# N32G05x register map
Vendor: Nationstech Ltd.; File version: 1.0
Registers are 32-bit, read-write, reset 0x0 unless marked. A register's access mark holds for its fields unless they carry their own. Offsets are from the block's base; [hi:lo] are bit positions; {n}, {i} and the like mark numbered series; 'fields as' and 'values as' point back to an identical list.

## RCC — Reset and clock control
Base 0x40021000
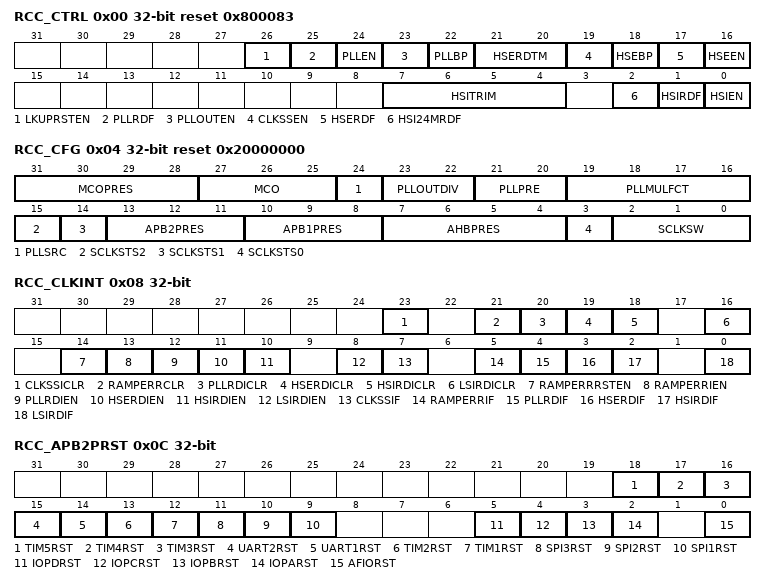
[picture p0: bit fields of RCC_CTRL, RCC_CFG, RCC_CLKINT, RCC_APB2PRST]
0x00 RCC_CTRL reset 0x800083 (reset mask 0x3CB00FB)
  [26] LKUPRSTEN, [25] PLLRDF, [24] PLLEN, [23] PLLOUTEN, [22] PLLBP, [21:20] HSERDTM, [19] CLKSSEN, [18] HSEBP, [17] HSERDF, [16] HSEEN, [7:4] HSITRIM, [2] HSI24MRDF, [1] HSIRDF, [0] HSIEN
0x04 RCC_CFG reset 0x20000000
  [31:28] MCOPRES, [27:25] MCO, [24] PLLSRC, [23:22] PLLOUTDIV, [21:20] PLLPRE, [19:16] PLLMULFCT, [15] SCLKSTS2, [14] SCLKSTS1, [13:11] APB2PRES, [10:8] APB1PRES, [7:4] AHBPRES, [3] SCLKSTS0, [2:0] SCLKSW
0x08 RCC_CLKINT
  [23] CLKSSICLR, [21] RAMPERRCLR, [20] PLLRDICLR, [19] HSERDICLR, [18] HSIRDICLR, [16] LSIRDICLR, [14] RAMPERRRSTEN, [13] RAMPERRIEN, [12] PLLRDIEN, [11] HSERDIEN, [10] HSIRDIEN, [8] LSIRDIEN, [7] CLKSSIF, [5] RAMPERRIF, [4] PLLRDIF, [3] HSERDIF, [2] HSIRDIF, [0] LSIRDIF
0x0C RCC_APB2PRST (reset mask 0x2769D)
  [18] TIM5RST, [17] TIM4RST, [16] TIM3RST, [15] UART2RST, [14] UART1RST, [13] TIM2RST, [12] TIM1RST, [11] SPI3RST, [10] SPI2RST, [9] SPI1RST, [5] IOPDRST, [4] IOPCRST, [3] IOPBRST, [2] IOPARST, [0] AFIORST
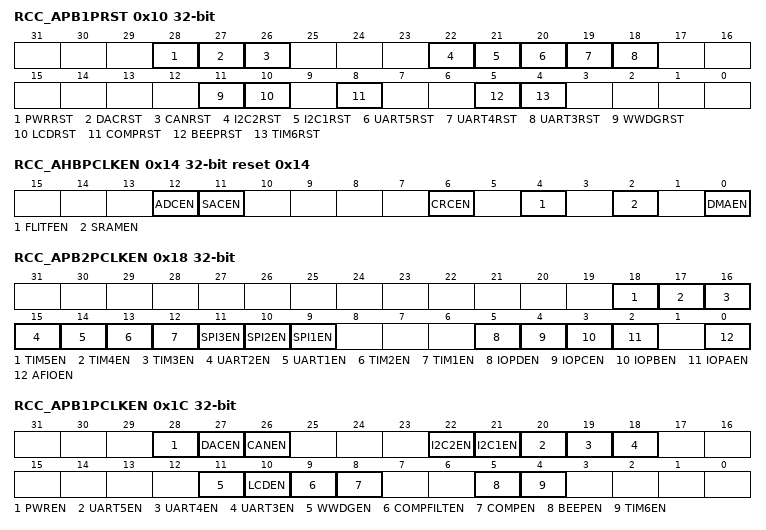
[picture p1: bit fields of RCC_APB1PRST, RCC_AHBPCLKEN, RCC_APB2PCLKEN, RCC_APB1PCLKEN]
0x10 RCC_APB1PRST (reset mask 0x1066083A)
  [28] PWRRST, [27] DACRST, [26] CANRST, [22] I2C2RST, [21] I2C1RST, [20] UART5RST, [19] UART4RST, [18] UART3RST, [11] WWDGRST, [10] LCDRST, [8] COMPRST, [5] BEEPRST, [4] TIM6RST
0x14 RCC_AHBPCLKEN reset 0x14 (reset mask 0x10F7)
  [12] ADCEN, [11] SACEN, [6] CRCEN, [4] FLITFEN, [2] SRAMEN, [0] DMAEN
0x18 RCC_APB2PCLKEN (reset mask 0x769D)
  [18] TIM5EN, [17] TIM4EN, [16] TIM3EN, [15] UART2EN, [14] UART1EN, [13] TIM2EN, [12] TIM1EN, [11] SPI3EN, [10] SPI2EN, [9] SPI1EN, [5] IOPDEN, [4] IOPCEN, [3] IOPBEN, [2] IOPAEN, [0] AFIOEN
0x1C RCC_APB1PCLKEN (reset mask 0x90660B3E)
  [28] PWREN, [27] DACEN, [26] CANEN, [22] I2C2EN, [21] I2C1EN, [20] UART5EN, [19] UART4EN, [18] UART3EN, [11] WWDGEN, [10] LCDEN, [9] COMPFILTEN, [8] COMPEN, [5] BEEPEN, [4] TIM6EN
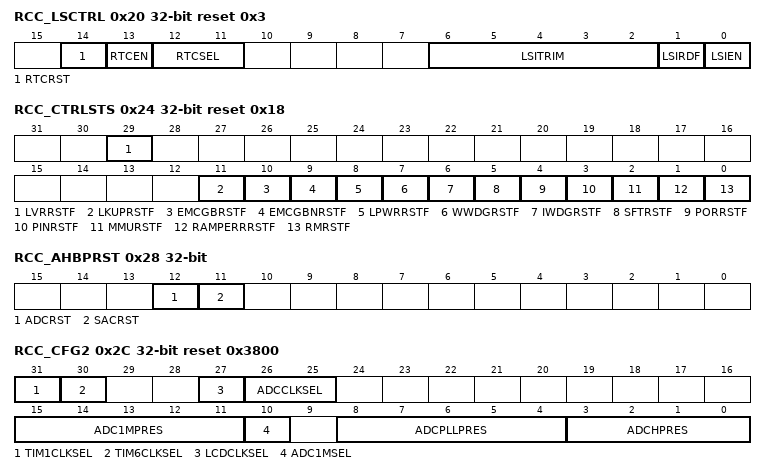
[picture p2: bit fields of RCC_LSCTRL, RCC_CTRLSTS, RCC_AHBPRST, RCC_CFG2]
0x20 RCC_LSCTRL reset 0x3 (reset mask 0x3FF)
  [14] RTCRST
  [13] RTCEN
  [12:11] RTCSEL
  [6:2] LSITRIM
  [1] LSIRDF — LSIRD
  [0] LSIEN
0x24 RCC_CTRLSTS reset 0x18 (reset mask 0xFFF)
  [29] LVRRSTF, [11] LKUPRSTF, [10] EMCGBRSTF, [9] EMCGBNRSTF, [8] LPWRRSTF, [7] WWDGRSTF, [6] IWDGRSTF, [5] SFTRSTF, [4] PORRSTF, [3] PINRSTF, [2] MMURSTF, [1] RAMPERRRSTF, [0] RMRSTF
0x28 RCC_AHBPRST (reset mask 0x10A0)
  [12] ADCRST, [11] SACRST
0x2C RCC_CFG2 reset 0x3800 (reset mask 0x8EE0FDFF)
  [31] TIM1CLKSEL, [30] TIM6CLKSEL, [27] LCDCLKSEL, [26:25] ADCCLKSEL, [15:11] ADC1MPRES, [10] ADC1MSEL, [8:4] ADCPLLPRES, [3:0] ADCHPRES
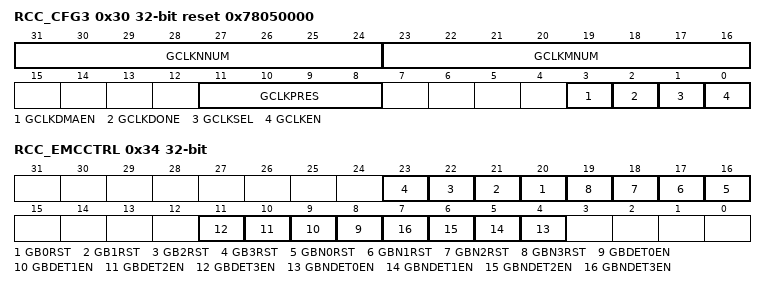
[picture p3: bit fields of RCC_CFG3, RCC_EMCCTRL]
0x30 RCC_CFG3 reset 0x78050000 (reset mask 0x8EE0FDFF)
  [31:24] GCLKNNUM, [23:16] GCLKMNUM, [11:8] GCLKPRES, [3] GCLKDMAEN, [2] GCLKDONE, [1] GCLKSEL, [0] GCLKEN
0x34 RCC_EMCCTRL
  [n+20] GB{n}RST (n=0..3), [n+16] GBN{n}RST (n=0..3), [n+8] GBDET{n}EN (n=0..3), [n+4] GBNDET{n}EN (n=0..3)

## RTC — Real time clock
Base 0x40002800
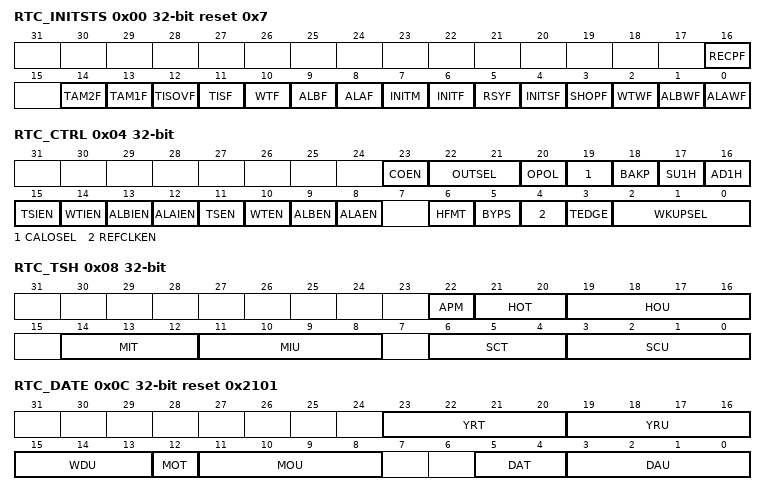
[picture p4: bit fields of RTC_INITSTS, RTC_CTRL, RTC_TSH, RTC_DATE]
0x00 RTC_INITSTS reset 0x7
  [16] RECPF, [14] TAM2F, [13] TAM1F, [12] TISOVF, [11] TISF, [10] WTF, [9] ALBF, [8] ALAF, [7] INITM, [6] INITF, [5] RSYF, [4] INITSF, [3] SHOPF, [2] WTWF, [1] ALBWF, [0] ALAWF
0x04 RTC_CTRL
  [23] COEN, [22:21] OUTSEL, [20] OPOL, [19] CALOSEL, [18] BAKP, [17] SU1H, [16] AD1H, [15] TSIEN, [14] WTIEN, [13] ALBIEN, [12] ALAIEN, [11] TSEN, [10] WTEN, [9] ALBEN, [8] ALAEN, [6] HFMT, [5] BYPS, [4] REFCLKEN, [3] TEDGE, [2:0] WKUPSEL
0x08 RTC_TSH
  [22] APM, [21:20] HOT, [19:16] HOU, [14:12] MIT, [11:8] MIU, [6:4] SCT, [3:0] SCU
0x0C RTC_DATE reset 0x2101
  [23:20] YRT, [19:16] YRU, [15:13] WDU, [12] MOT, [11:8] MOU, [5:4] DAT, [3:0] DAU
0x10 RTC_WRP
  [7:0] PKEY
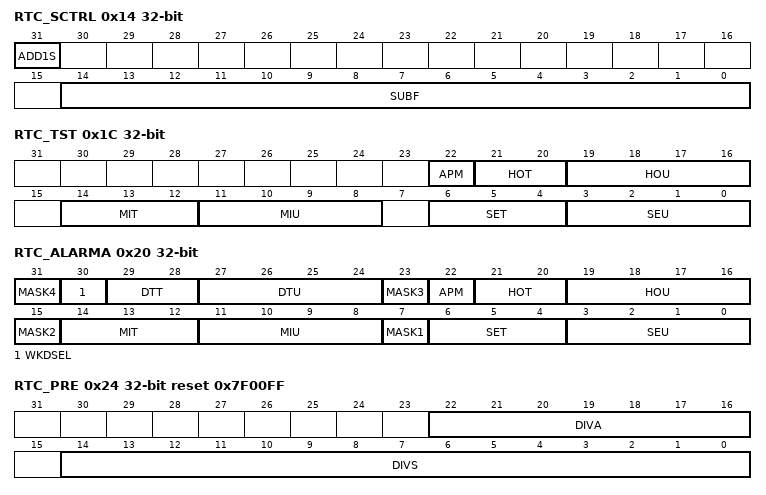
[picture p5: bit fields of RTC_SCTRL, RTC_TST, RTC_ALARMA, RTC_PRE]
0x14 RTC_SCTRL
  [31] ADD1S, [14:0] SUBF
0x18 RTC_SUBS
  [15:0] SS
0x1C RTC_TST (reset mask 0x7F)
  [22] APM, [21:20] HOT, [19:16] HOU, [14:12] MIT, [11:8] MIU, [6:4] SET, [3:0] SEU
0x20 RTC_ALARMA
  [8n-1] MASK{n} (n=1..4), [30] WKDSEL, [29:28] DTT, [27:24] DTU, [22] APM, [21:20] HOT, [19:16] HOU, [14:12] MIT, [11:8] MIU, [6:4] SET, [3:0] SEU
0x24 RTC_PRE reset 0x7F00FF
  [22:16] DIVA, [14:0] DIVS
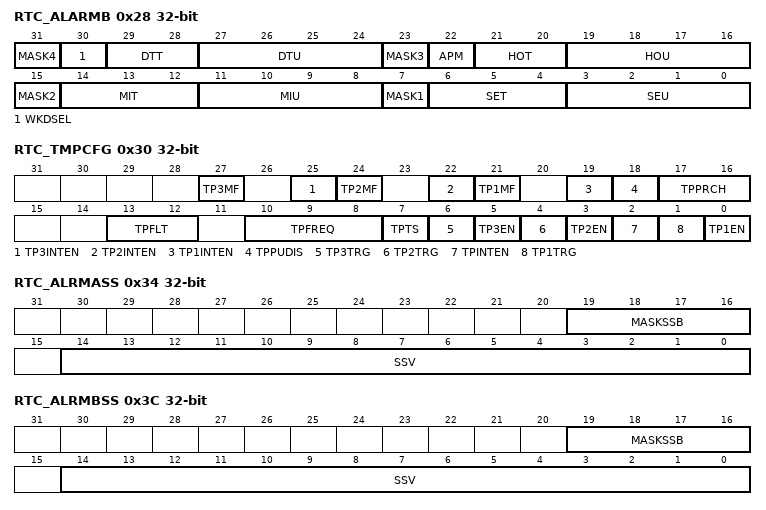
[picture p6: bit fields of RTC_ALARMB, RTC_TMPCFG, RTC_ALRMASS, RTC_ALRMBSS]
0x28 RTC_ALARMB
  fields as RTC_ALARMA
0x2C RTC_WKUPT reset 0xFFFF
  [15:0] WKUPT
0x30 RTC_TMPCFG (reset mask 0x2DFF9F)
  [27] TP3MF, [25] TP3INTEN, [24] TP2MF, [22] TP2INTEN, [21] TP1MF, [19] TP1INTEN, [18] TPPUDIS, [17:16] TPPRCH, [13:12] TPFLT, [10:8] TPFREQ, [7] TPTS, [6] TP3TRG, [5] TP3EN, [4] TP2TRG, [3] TP2EN, [2] TPINTEN, [1] TP1TRG, [0] TP1EN
0x34 RTC_ALRMASS
  [19:16] MASKSSB, [14:0] SSV
0x38 RTC_OPT
  [0] TYPE
0x3C RTC_ALRMBSS
  [19:16] MASKSSB, [14:0] SSV
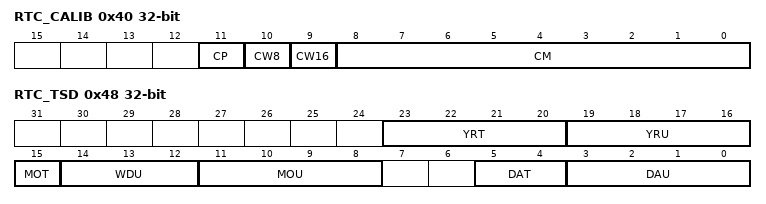
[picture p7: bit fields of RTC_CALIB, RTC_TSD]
0x40 RTC_CALIB (reset mask 0xFF)
  [11] CP, [10] CW8, [9] CW16, [8:0] CM
0x44 RTC_TSSS
  [15:0] SSE
0x48 RTC_TSD
  [23:20] YRT, [19:16] YRU, [15] MOT, [14:12] WDU, [11:8] MOU, [5:4] DAT, [3:0] DAU
